# CY8C5868AXI_LP035 register map
File version: 0.1
CY8C58LP
Registers are 8-bit, read-write, no defined reset value unless marked. A register's access mark holds for its fields unless they carry their own. Offsets are from the block's base; lines under a group give offsets from that group; [hi:lo] are bit positions; {n}, {i} and the like mark numbered series; 'fields as' and 'values as' point back to an identical list; <NAME> marks a mode.

## Memory map
0x00000000 I2S
0x00000000 ADC — SAR ADC
0x00000000 DAC

## I2S
Base 0x00000000
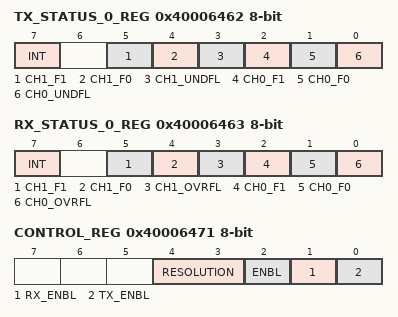
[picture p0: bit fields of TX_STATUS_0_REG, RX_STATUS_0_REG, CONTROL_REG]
0x40006462 TX_STATUS_0_REG
  [7] INT ro — Interrupt bit
  [5] CH1_F1 ro — Stereo channel 1 FIFO 1 state
    0=FULL; 1=NOT_FULL
  [4] CH1_F0 ro — Stereo channel 1 FIFO 0 state
    0=FULL; 1=NOT_FULL
  [3] CH1_UNDFL ro — Stereo channel 1 FIFO underflow
    0=NO_UNDERFLOW; 1=UNDERFLOW
  [2] CH0_F1 ro — Stereo channel 0 FIFO 1 state
    0=FULL; 1=NOT_FULL
  [1] CH0_F0 ro — Stereo channel 0 FIFO 0 state
    0=FULL; 1=NOT_FULL
  [0] CH0_UNDFL ro — Stereo channel 0 FIFO underflow
    0=NO_UNDERFLOW; 1=UNDERFLOW
0x40006463 RX_STATUS_0_REG
  [7] INT ro — Interrupt bit
  [5] CH1_F1 ro — Stereo channel 1 FIFO 1 state
    0=EMPTY; 1=NOT_EMPTY
  [4] CH1_F0 ro — Stereo channel 1 FIFO 0 state
    0=EMPTY; 1=NOT_EMPTY
  [3] CH1_OVRFL ro — Stereo channel 1 FIFO overflow
    0=NO_OVERFLOW; 1=OVERFLOW
  [2] CH0_F1 ro — Stereo channel 0 FIFO 1 state
    0=EMPTY; 1=NOT_EMPTY
  [1] CH0_F0 ro — Stereo channel 0 FIFO 0 state
    0=EMPTY; 1=NOT_EMPTY
  [0] CH0_OVRFL ro — Stereo channel 0 FIFO overflow
    0=NO_OVERFLOW; 1=OVERFLOW
0x40006471 CONTROL_REG
  [4:3] RESOLUTION — Specifies data bits value. Applicable only if dynamic bit resolution is selected.
    0=Cy8_BIT; 1=Cy16_BIT; 2=Cy24_BIT; 3=Cy32_BIT
  [2] ENBL — Starts the generation of the WS and SCK outputs.
    1=ENABLED; 0=DISABLED
  [1] RX_ENBL — Enables Rx direction. Applicable only if Rx direction presents for the component.
    1=ENABLED; 0=DISABLED
  [0] TX_ENBL — Enables Tx direction. Applicable only if Tx direction presents for the component.
    1=ENABLED; 0=DISABLED

## ADC — SAR ADC
Base 0x00000000
0x40004614 SAR_TR0 — SAR trim register
{0x40005900+i} SAR_CSR{i} (i=0..6) — SAR status and control register {i}
0x40005B20 SAR_SW0 — SAR Analog Routing Register 0
{0x40005B20+i} SAR_SW{i} (i=2..4) — SAR Analog Routing Register {i}
0x40005B26 SAR_SW6 — SAR Analog Routing Register 6
0x40005B27 SAR_CLK — SAR Clock Selection Register
0x40005BA0 SAR_WRK 16-bit — SAR working register

## DAC
Base 0x00000000
0x400043A8 VDAC8_PM_ACT_CFG — Active Power Mode Configuration Register 8
  [4:0] en_dac — Enable DAC block(s). Populated subsystems are counted from the LSB
0x400043B8 VDAC8_PM_STBY_CFG — Standby Power Mode Configuration Register 8
  fields as VDAC8_PM_ACT_CFG
0x4000460A VDAC8_TR
  [7:0] tr — 8 Calibration bits
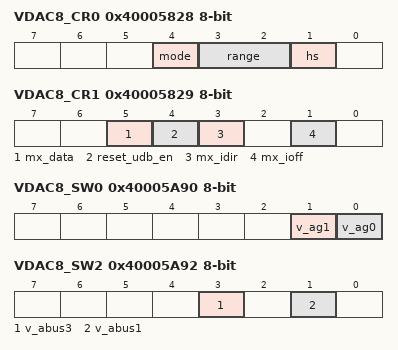
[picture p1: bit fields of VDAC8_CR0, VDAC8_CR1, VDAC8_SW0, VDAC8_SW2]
0x40005828 VDAC8_CR0 — DAC Block Control Register 0
  [4] mode ro — Mode Bit
    0=DAC_MODE_V (voltage DAC); 1=DAC_MODE_I (current DAC)
  [3:2] range — Ranges for mode=0 (VDAC) and mode=1 (IDAC)
    0=DAC_RANGE_0 (x0=0V to 4*vref (1.024V); 0 to 31.875uA); 1=DAC_RANGE_1 (x1=0V to 16*vref (4.096V); 0 to 255uA); 2=DAC_RANGE_2 (x0=0V to 4*vref (1.024V); 0 to 2.040mA); 3=DAC_RANGE_3 (x1=0V to 16*vref (4.096V); not used)
  [1] hs — High Speed Bit
    0=DAC_HS_LOWPOWER (regular (low power)); 1=DAC_HS_HIGHSPEED (high speed (higher power))
0x40005829 VDAC8_CR1 — DAC Block Control Register 1
  [5] mx_data — Select DATA source
    0=MX_DATA_REG (Select register source (DACxn_D)); 1=MX_DATA_UDB (Select UDB source)
  [4] reset_udb_en — DAC reset enable
    0=RESET_UDB_EN_DISABLE (Disable DAC Reset Source from UDB (System reset always resets)); 1=RESET_UDB_EN_ENABLE (Enable DAC Reset Source from UDB)
  [3] mx_idir — Mux selection for DAC current direction control
    0=MX_IDIR_REG (Register source idirbit selected); 1=MX_IDIR_UDB (UDB ictrl selected)
  [1] mx_ioff — Mux selection for DAC current off control
    0=MX_IOFF_REG (Register source ioffbit selected); 1=MX_IOFF_UDB (UDB ictrl selected)
0x40005A90 VDAC8_SW0 — DAC Analog Routing Register 0
  [1] v_ag1 — Connect voltage output to analog global of same side
    0=AG_NC (not connected); 1=AG_CONNECTED (Connect to Analog Global)
  [0] v_ag0 — Connect voltage output to analog global of same side
    values as v_ag1
0x40005A92 VDAC8_SW2 — DAC Analog Routing Register 2
  [3] v_abus3 — Connect voltage output to analog (local) bus of the same side
    0=ABUS_NC (not connected); 1=ABUS_CONNECTED (Connect to Analog (local) Bus)
  [1] v_abus1 — Connect voltage output to analog (local) bus of the same side
    values as v_abus3
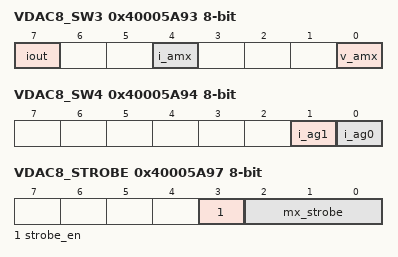
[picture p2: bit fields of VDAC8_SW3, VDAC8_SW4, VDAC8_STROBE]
0x40005A93 VDAC8_SW3 — DAC Analog Routing Register 3
  [7] iout — Connect current output to pad
    0=IOUT_NC (not connected); 1=IOUT_CONNECT (Connect to pad)
  [4] i_amx — Connect current output to Analog Mux Bus
    0=AMX_NC (not connected); 1=AMX_CONNECTED (Connect to AMUXBUS)
  [0] v_amx — Connect voltage output to Analog Mux Bus
    values as i_amx
0x40005A94 VDAC8_SW4 — DAC Analog Routing Register 4
  [1] i_ag1 — Connect current output to analog global of same side
    values as VDAC8_SW0.v_ag1
  [0] i_ag0 — Connect current output to analog global of same side
    values as VDAC8_SW0.v_ag1
0x40005A97 VDAC8_STROBE — DAC Strobe Register
  [3] strobe_en — Strobe gating control (See mx_strobe==3'h0)
    0=disable strobe; 1=enable strobe
  [2:0] mx_strobe — Strobe source selection
    0=MX_STROBE_BUSWRITE (Select bus write strobe source (Enable gater regardless of strobe_en setting)); 1=MX_STROBE_UDB_SRC (Select UDB strobe source); 2=MX_STROBE_NC_2 (NC); 3=MX_STROBE_NC_3 (NC); {v}=MX_STROBE_CLK_A{v-4}_DIG (Select clk_a{v-4}_dig) (v=4..7)
0x40005B82 VDAC8_DATA — DAC Data Register
  [7:0] data — 8 DAC Data bits
